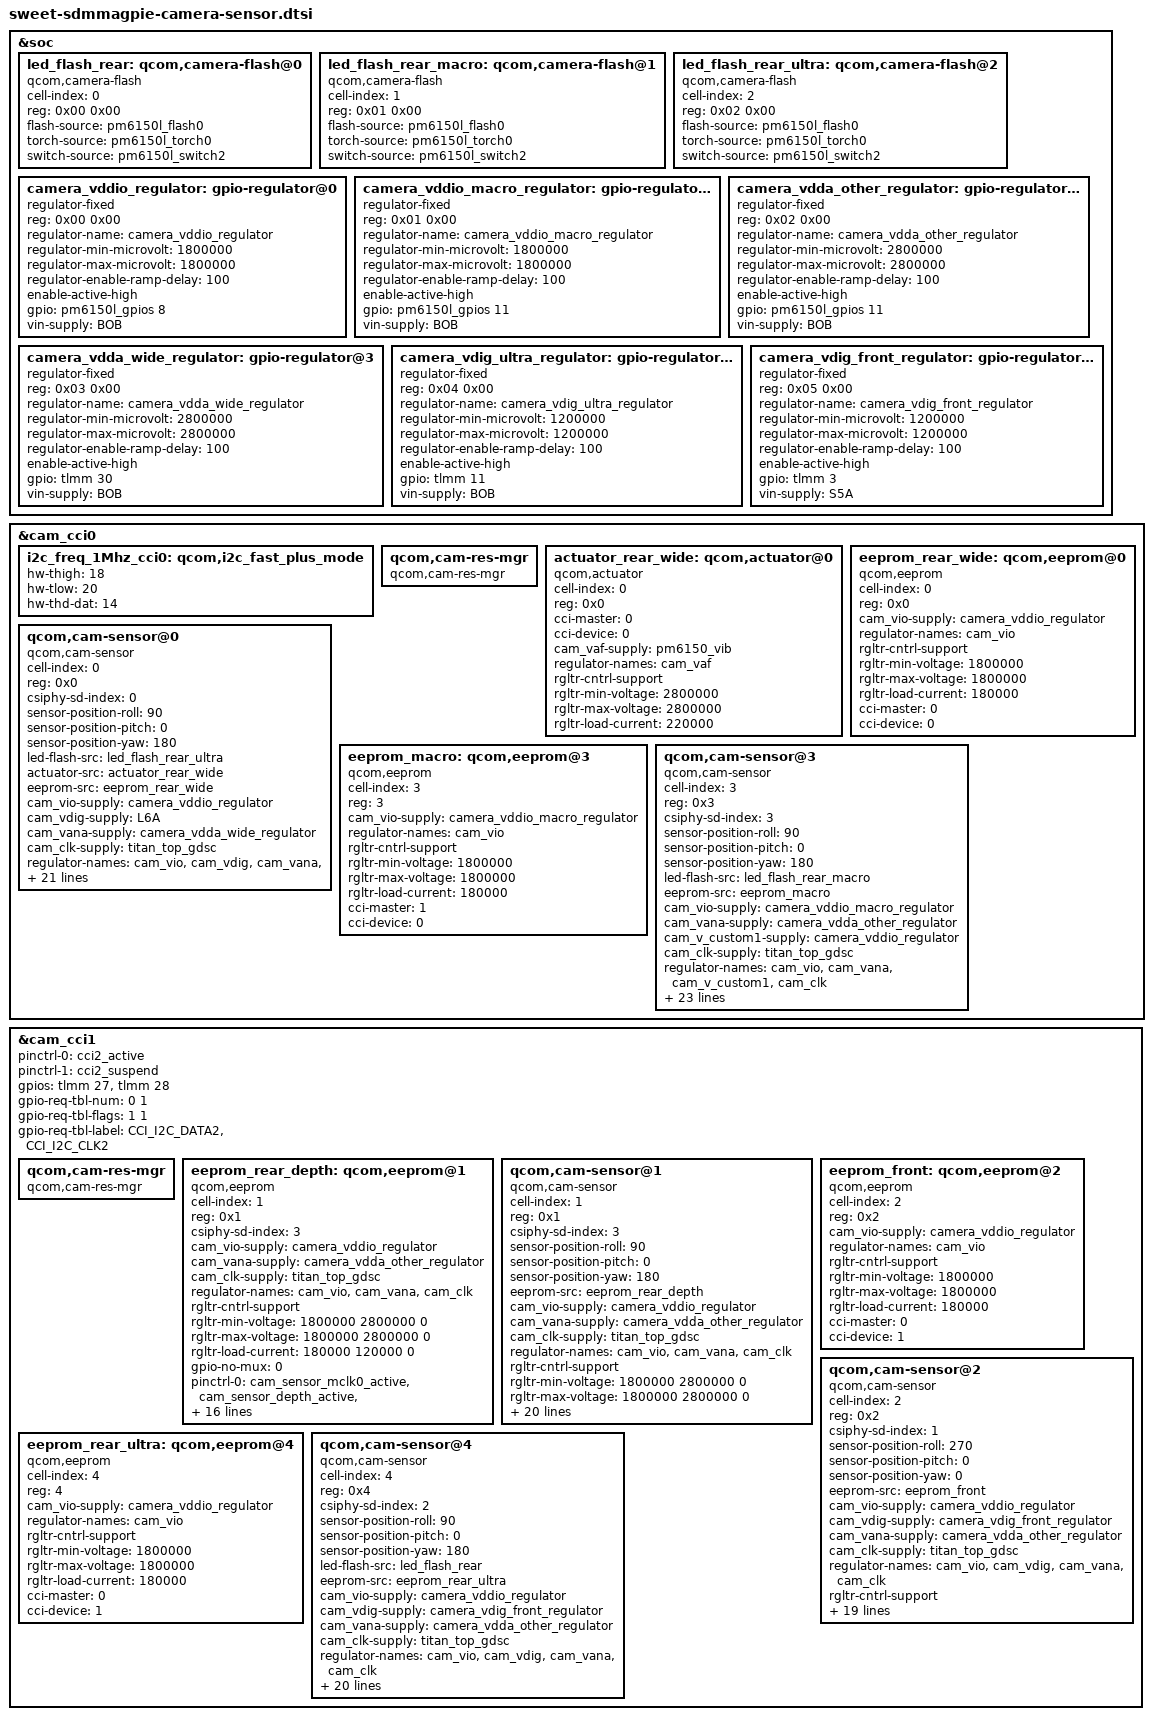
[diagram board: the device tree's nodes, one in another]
/*
 * Copyright (c) 2018, The Linux Foundation. All rights reserved.
 *
 * This program is free software; you can redistribute it and/or modify
 * it under the terms of the GNU General Public License version 2 and
 * only version 2 as published by the Free Software Foundation.
 *
 * This program is distributed in the hope that it will be useful,
 * but WITHOUT ANY WARRANTY; without even the implied warranty of
 * MERCHANTABILITY or FITNESS FOR A PARTICULAR PURPOSE.  See the
 * GNU General Public License for more details.
 */

#include <dt-bindings/clock/qcom,camcc-sdmmagpie.h>
#include "sweet-sdmmagpie-camera-pinctrl.dtsi"

&soc {
	led_flash_rear: qcom,camera-flash@0 {
		cell-index = <0>;
		reg = <0x00 0x00>;
		compatible = "qcom,camera-flash";
		flash-source = <&pm6150l_flash0>;
		torch-source = <&pm6150l_torch0>;
		switch-source = <&pm6150l_switch2>;
		status = "ok";
	};

	led_flash_rear_macro: qcom,camera-flash@1 {
		cell-index = <1>;
		reg = <0x01 0x00>;
		compatible = "qcom,camera-flash";
		flash-source = <&pm6150l_flash0>;
		torch-source = <&pm6150l_torch0>;
		switch-source = <&pm6150l_switch2>;
		status = "ok";
	};

	led_flash_rear_ultra: qcom,camera-flash@2 {
		cell-index = <2>;
		reg = <0x02 0x00>;
		compatible = "qcom,camera-flash";
		flash-source = <&pm6150l_flash0>;
		torch-source = <&pm6150l_torch0>;
		switch-source = <&pm6150l_switch2>;
		status = "ok";
	};

	//wide/ultra/front/depth/mipi sel  iovdd
	camera_vddio_regulator: gpio-regulator@0 {
		compatible = "regulator-fixed";
		reg = <0x00 0x00>;
		regulator-name = "camera_vddio_regulator";
		regulator-min-microvolt = <1800000>;
		regulator-max-microvolt = <1800000>;
		regulator-enable-ramp-delay = <100>;
		enable-active-high;
		gpio = <&pm6150l_gpios 8 0>;
		vin-supply = <&BOB>;
	};

	//macro iovdd
	camera_vddio_macro_regulator: gpio-regulator@1 {
		compatible = "regulator-fixed";
		reg = <0x01 0x00>;
		regulator-name = "camera_vddio_macro_regulator";
		regulator-min-microvolt = <1800000>;
		regulator-max-microvolt = <1800000>;
		regulator-enable-ramp-delay = <100>;
		enable-active-high;
		gpio = <&pm6150l_gpios 11 0>;
		vin-supply = <&BOB>;
	};

	//ultra/front/macro/depth avdd
	camera_vdda_other_regulator: gpio-regulator@2 {
		compatible = "regulator-fixed";
		reg = <0x02 0x00>;
		regulator-name = "camera_vdda_other_regulator";
		regulator-min-microvolt = <2800000>;
		regulator-max-microvolt = <2800000>;
		regulator-enable-ramp-delay = <100>;
		enable-active-high;
		gpio = <&pm6150l_gpios 11 0>;
		vin-supply = <&BOB>;
	};

	camera_vdda_wide_regulator: gpio-regulator@3 {
		compatible = "regulator-fixed";
		reg = <0x03 0x00>;
		regulator-name = "camera_vdda_wide_regulator";
		regulator-min-microvolt = <2800000>;
		regulator-max-microvolt = <2800000>;
		regulator-enable-ramp-delay = <100>;
		enable-active-high;
		gpio = <&tlmm 30 0>;
		vin-supply = <&BOB>;
	};

	camera_vdig_ultra_regulator: gpio-regulator@4 {
		compatible = "regulator-fixed";
		reg = <0x04 0x00>;
		regulator-name = "camera_vdig_ultra_regulator";
		regulator-min-microvolt = <1200000>;
		regulator-max-microvolt = <1200000>;
		regulator-enable-ramp-delay = <100>;
		enable-active-high;
		gpio = <&tlmm 11 0>;
		vin-supply = <&BOB>;
	};

	camera_vdig_front_regulator: gpio-regulator@5 {
		compatible = "regulator-fixed";
		reg = <0x05 0x00>;
		regulator-name = "camera_vdig_front_regulator";
		regulator-min-microvolt = <1200000>;
		regulator-max-microvolt = <1200000>;
		regulator-enable-ramp-delay = <100>;
		enable-active-high;
		gpio = <&tlmm 3 0>;
		vin-supply = <&S5A>;
	};
};

&cam_cci0 {
	i2c_freq_1Mhz_cci0: qcom,i2c_fast_plus_mode {
		hw-thigh = <18>;
		hw-tlow = <20>;
		hw-thd-dat = <14>;
	};
};

&cam_cci0 {
	qcom,cam-res-mgr {
		compatible = "qcom,cam-res-mgr";
		status = "ok";
	};

	actuator_rear_wide: qcom,actuator@0 {
		cell-index = <0>;
		reg = <0x0>;
		compatible = "qcom,actuator";
		cci-master = <0>;
		cci-device = <0>;
		cam_vaf-supply = <&pm6150_vib>;
		regulator-names = "cam_vaf";
		rgltr-cntrl-support;
		rgltr-min-voltage = <2800000>;
		rgltr-max-voltage = <2800000>;
		rgltr-load-current = <220000>;
	};

	 eeprom_rear_wide: qcom,eeprom@0 {
		cell-index = <0>;
		reg = <0x0>;
		compatible = "qcom,eeprom";
		cam_vio-supply = <&camera_vddio_regulator>;
		regulator-names = "cam_vio";
		rgltr-cntrl-support;
		rgltr-min-voltage = <1800000>;
		rgltr-max-voltage = <1800000>;
		rgltr-load-current = <180000>;
		cci-master = <0>;
		cci-device = <0>;
		status = "ok";
	};

	qcom,cam-sensor@0 {//Wide
		cell-index = <0>;
		reg = <0x0>;
		compatible = "qcom,cam-sensor";
		csiphy-sd-index = <0>;
		sensor-position-roll = <90>;
		sensor-position-pitch = <0>;
		sensor-position-yaw = <180>;
		led-flash-src = <&led_flash_rear_ultra>;
		actuator-src = <&actuator_rear_wide>;
		eeprom-src = <&eeprom_rear_wide>;
		cam_vio-supply = <&camera_vddio_regulator>;
		cam_vdig-supply = <&L6A>;
		cam_vana-supply = <&camera_vdda_wide_regulator>;
		cam_clk-supply = <&titan_top_gdsc>;
		regulator-names = "cam_vio", "cam_vdig", "cam_vana", "cam_clk";
		rgltr-cntrl-support;
		rgltr-min-voltage = <1800000 1050000 2800000 0>;
		rgltr-max-voltage = <1800000 1050000 2800000 0>;
		rgltr-load-current = <180000 105000 120000 0>;
		gpio-no-mux = <0>;
		pinctrl-names = "cam_default", "cam_suspend";
		pinctrl-0 = <&cam_sensor_mclk2_active
		             &cam_sensor_wide_active>;
		pinctrl-1 = <&cam_sensor_mclk2_suspend
		             &cam_sensor_wide_suspend>;
		gpios = <&tlmm 15 0>,	//MCLK
		        <&tlmm 26 0>;	//RST
		gpio-reset = <1>;
		gpio-req-tbl-num = <0 1>;
		gpio-req-tbl-flags = <1 0>;
		gpio-req-tbl-label = "CAMIF_MCLK2",
		                     "CAMW_RESET";
		sensor-mode = <0>;
		cci-master = <0>;
		cci-device = <0>;
		status = "ok";
		clocks = <&clock_camcc CAM_CC_MCLK2_CLK>;
		clock-names = "cam_clk";
		clock-cntl-level = "turbo";
		clock-rates = <19200000>;
	};


	eeprom_macro: qcom,eeprom@3 {
		cell-index = <3>;
		reg = <3>;
		compatible = "qcom,eeprom";
		cam_vio-supply = <&camera_vddio_macro_regulator>;
		regulator-names = "cam_vio";
		rgltr-cntrl-support;
		rgltr-min-voltage = <1800000>;
		rgltr-max-voltage = <1800000>;
		rgltr-load-current = <180000>;
		cci-master = <1>;
		cci-device = <0>;
		status = "ok";
	};

	qcom,cam-sensor@3 {//Macro
		cell-index = <3>;
		reg = <0x3>;
		compatible = "qcom,cam-sensor";
		csiphy-sd-index = <3>;
		sensor-position-roll = <90>;
		sensor-position-pitch = <0>;
		sensor-position-yaw = <180>;
		led-flash-src = <&led_flash_rear_macro>;
		eeprom-src = <&eeprom_macro>;
		cam_vio-supply = <&camera_vddio_macro_regulator>;
		cam_vana-supply = <&camera_vdda_other_regulator>;
		cam_v_custom1-supply = <&camera_vddio_regulator>;
		cam_clk-supply = <&titan_top_gdsc>;
		regulator-names = "cam_vio", "cam_vana","cam_v_custom1","cam_clk";
		rgltr-cntrl-support;
		rgltr-min-voltage = <1800000 2800000 1800000 0>;
		rgltr-max-voltage = <1800000 2800000 1800000 0>;
		rgltr-load-current = <180000 120000 180000 0>;
		gpio-no-mux = <0>;
		pinctrl-names = "cam_default", "cam_suspend";
		pinctrl-0 = <&cam_sensor_mclk3_active
		             &cam_sensor_macro_active
		             &cam_sensor_mipi_switch_sel_high>;
		pinctrl-1 = <&cam_sensor_mclk3_suspend
		             &cam_sensor_macro_suspend
		             &cam_sensor_mipi_switch_sel_low>;
		gpios = <&tlmm 16 0>,	//MCLK
		        <&tlmm 24 0>,	//RST
		        <&tlmm 88 0>;	//enable: MIPI SEL, active high
		gpio-reset = <1>;
		gpio-custom1 = <2>;	//used as MIPI SEL
		gpio-req-tbl-num = <0 1 2>;
		gpio-req-tbl-flags = <1 0 0>;
		gpio-req-tbl-label = "CAMIF_MCLK3",
		                     "CAMM_RESET",
		                     "CAMM_CUSTOM1";
		cci-master = <1>;
		cci-device = <0>;
		status = "ok";
		clocks = <&clock_camcc CAM_CC_MCLK3_CLK>;
		clock-names = "cam_clk";
		clock-cntl-level = "turbo";
		clock-rates = <19200000>;
	};
};

&cam_cci1 {
	status = "ok";
	pinctrl-names = "cam_default", "cam_suspend";
	pinctrl-0 = <&cci2_active>;
	pinctrl-1 = <&cci2_suspend>;
	gpios = <&tlmm 27 0>,
		        <&tlmm 28 0>;
	gpio-req-tbl-num = <0 1>;
	gpio-req-tbl-flags = <1 1>;
	gpio-req-tbl-label = "CCI_I2C_DATA2",
		                     "CCI_I2C_CLK2";

	qcom,cam-res-mgr {
		compatible = "qcom,cam-res-mgr";
		status = "ok";
	};

	eeprom_rear_depth: qcom,eeprom@1 {
		cell-index = <1>;
		reg = <0x1>;
		compatible = "qcom,eeprom";
		csiphy-sd-index = <3>;
		cam_vio-supply = <&camera_vddio_regulator>;
		cam_vana-supply = <&camera_vdda_other_regulator>;
		cam_clk-supply = <&titan_top_gdsc>;
		regulator-names = "cam_vio", "cam_vana", "cam_clk";
		rgltr-cntrl-support;
		rgltr-min-voltage = <1800000 2800000 0>;
		rgltr-max-voltage = <1800000 2800000 0>;
		rgltr-load-current = <180000 120000 0>;
		gpio-no-mux = <0>;
		pinctrl-names = "cam_default", "cam_suspend";
		pinctrl-0 = <&cam_sensor_mclk0_active
		             &cam_sensor_depth_active 
		             &cam_sensor_mipi_switch_sel_low>;
		pinctrl-1 = <&cam_sensor_mclk0_suspend
		             &cam_sensor_depth_suspend
		             &cam_sensor_mipi_switch_sel_high>;
		gpios = <&tlmm 13 0>,	//MCLK
		        <&tlmm 21 0>,	//RST
		        <&tlmm 88 0>;	//enable: MIPI SEL, active low
		gpio-reset = <1>;
		gpio-custom1 = <2>;	//used as MIPI SEL
		gpio-req-tbl-num = <0 1 2>;
		gpio-req-tbl-flags = <1 0 0>;
		gpio-req-tbl-label = "CAMIF_MCLK0",
		                     "CAMD_RESET",
		                     "CAMD_CUSTOM1";
		cci-master = <0>;
		cci-device = <1>;
		status = "ok";
		clocks = <&clock_camcc CAM_CC_MCLK0_CLK>;
		clock-names = "cam_clk";
		clock-cntl-level = "turbo";
		clock-rates = <19200000>;
	};

	qcom,cam-sensor@1 {//Depth
		cell-index = <1>;
		reg = <0x1>;
		compatible = "qcom,cam-sensor";
		csiphy-sd-index = <3>;
		sensor-position-roll = <90>;
		sensor-position-pitch = <0>;
		sensor-position-yaw = <180>;
		eeprom-src = <&eeprom_rear_depth>;
		cam_vio-supply = <&camera_vddio_regulator>;
		cam_vana-supply = <&camera_vdda_other_regulator>;
		cam_clk-supply = <&titan_top_gdsc>;
		regulator-names = "cam_vio", "cam_vana", "cam_clk";
		rgltr-cntrl-support;
		rgltr-min-voltage = <1800000 2800000 0>;
		rgltr-max-voltage = <1800000 2800000 0>;
		rgltr-load-current = <180000 120000 0>;
		gpio-no-mux = <0>;
		pinctrl-names = "cam_default", "cam_suspend";
		pinctrl-0 = <&cam_sensor_mclk0_active
		             &cam_sensor_depth_active 
		             &cam_sensor_mipi_switch_sel_low>;
		pinctrl-1 = <&cam_sensor_mclk0_suspend
		             &cam_sensor_depth_suspend
		             &cam_sensor_mipi_switch_sel_high>;
		gpios = <&tlmm 13 0>,	//MCLK
		        <&tlmm 21 0>,	//RST
		        <&tlmm 88 0>;	//enable: MIPI SEL, active high
		gpio-reset = <1>;
		gpio-custom1 = <2>;	//used as MIPI SEL
		gpio-req-tbl-num = <0 1 2>;
		gpio-req-tbl-flags = <1 0 0>;
		gpio-req-tbl-label = "CAMIF_MCLK0",
		                     "CAMD_RESET",
		                     "CAMD_CUSTOM1";
		cci-master = <0>;
		cci-device = <1>;
		status = "ok";
		clocks = <&clock_camcc CAM_CC_MCLK0_CLK>;
		clock-names = "cam_clk";
		clock-cntl-level = "turbo";
		clock-rates = <19200000>;
	};


	eeprom_front: qcom,eeprom@2 {
		cell-index = <2>;
		reg = <0x2>;
		compatible = "qcom,eeprom";
		cam_vio-supply = <&camera_vddio_regulator>;
		regulator-names = "cam_vio";
		rgltr-cntrl-support;
		rgltr-min-voltage = <1800000>;
		rgltr-max-voltage = <1800000>;
		rgltr-load-current = <180000>;
		cci-master = <0>;
		cci-device = <1>;
		status = "ok";
	};

	qcom,cam-sensor@2 {//Front
		cell-index = <2>;
		reg = <0x2>;
		compatible = "qcom,cam-sensor";
		csiphy-sd-index = <1>;
		sensor-position-roll = <270>;
		sensor-position-pitch = <0>;
		sensor-position-yaw = <0>;
		eeprom-src = <&eeprom_front>;
		cam_vio-supply = <&camera_vddio_regulator>;
		cam_vdig-supply = <&camera_vdig_front_regulator>;
		cam_vana-supply = <&camera_vdda_other_regulator>;
		cam_clk-supply = <&titan_top_gdsc>;
		regulator-names = "cam_vio","cam_vdig", "cam_vana","cam_clk";
		rgltr-cntrl-support;
		rgltr-min-voltage = <1800000 1200000 2800000 0>;
		rgltr-max-voltage = <1800000 1200000 2800000 0>;
		rgltr-load-current = <180000 110000 120000 0>;
		gpio-no-mux = <0>;
		pinctrl-names = "cam_default", "cam_suspend";
		pinctrl-0 = <&cam_sensor_mclk0_active
		             &cam_sensor_front_active>;
		pinctrl-1 = <&cam_sensor_mclk0_suspend
		             &cam_sensor_front_suspend>;
		gpios = <&tlmm 13 0>,			//MCLK
		        <&tlmm 23 0>;			//RST
		gpio-reset = <1>;
		gpio-req-tbl-num = <0 1>;
		gpio-req-tbl-flags = <1 0>;
		gpio-req-tbl-label = "CAMIF_MCLK0",
		                     "CAMF_RESET";
		sensor-mode = <0>;
		cci-master = <0>;
		cci-device = <1>;
		status = "ok";
		clocks = <&clock_camcc CAM_CC_MCLK0_CLK>;
		clock-names = "cam_clk";
		clock-cntl-level = "turbo";
		clock-rates = <19200000>;
	};


	eeprom_rear_ultra: qcom,eeprom@4 {
		cell-index = <4>;
		reg = <4>;
		compatible = "qcom,eeprom";
		cam_vio-supply = <&camera_vddio_regulator>;
		regulator-names = "cam_vio";
		rgltr-cntrl-support;
		rgltr-min-voltage = <1800000>;
		rgltr-max-voltage = <1800000>;
		rgltr-load-current = <180000>;
		cci-master = <0>;
		cci-device = <1>;
		status = "ok";
	};

	qcom,cam-sensor@4 {//Ultra
		cell-index = <4>;
		reg = <0x4>;
		compatible = "qcom,cam-sensor";
		csiphy-sd-index = <2>;
		sensor-position-roll = <90>;
		sensor-position-pitch = <0>;
		sensor-position-yaw = <180>;
		led-flash-src = <&led_flash_rear>;
		eeprom-src = <&eeprom_rear_ultra>;
		cam_vio-supply = <&camera_vddio_regulator>;
		cam_vdig-supply = <&camera_vdig_front_regulator>;
		cam_vana-supply = <&camera_vdda_other_regulator>;
		cam_clk-supply = <&titan_top_gdsc>;
		regulator-names = "cam_vio", "cam_vdig", "cam_vana", "cam_clk";
		rgltr-cntrl-support;
		rgltr-min-voltage = <1800000 1200000 2800000 0>;
		rgltr-max-voltage = <1800000 1200000 2800000 0>;
		rgltr-load-current = <180000 120000 120000 0>;
		gpio-no-mux = <0>;
		pinctrl-names = "cam_default", "cam_suspend";
		pinctrl-0 = <&cam_sensor_mclk1_active
		             &cam_sensor_ultra_active>;
		pinctrl-1 = <&cam_sensor_mclk1_suspend
		             &cam_sensor_ultra_suspend>;
		gpios = <&tlmm 14 0>,			//MCLK
		        <&tlmm 25 0>;			//RST
		gpio-reset = <1>;
		gpio-req-tbl-num = <0 1>;
		gpio-req-tbl-flags = <1 0>;
		gpio-req-tbl-label = "CAMIF_MCLK1",
		                     "CAMU_RESET";
		sensor-mode = <0>;
		cci-master = <0>;
		cci-device = <1>;
		status = "ok";
		clocks = <&clock_camcc CAM_CC_MCLK1_CLK>;
		clock-names = "cam_clk";
		clock-cntl-level = "turbo";
		clock-rates = <19200000>;
	};

};
